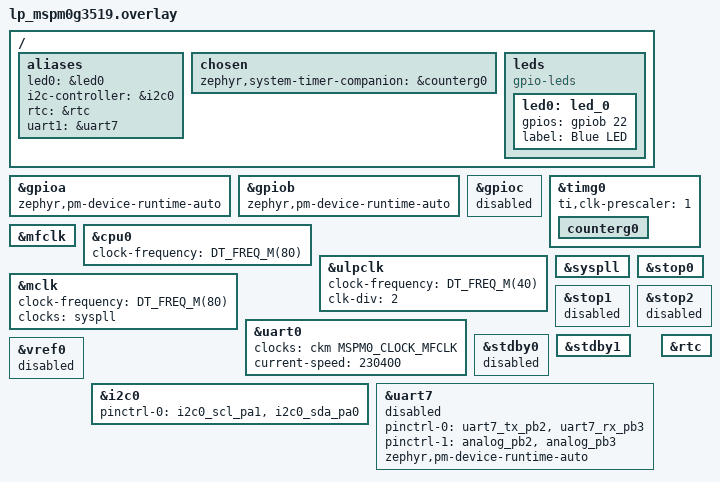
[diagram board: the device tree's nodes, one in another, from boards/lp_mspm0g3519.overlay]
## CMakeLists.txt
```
# SPDX-License-Identifier: Apache-2.0

cmake_minimum_required(VERSION 3.20.0)
find_package(Zephyr REQUIRED HINTS $ENV{ZEPHYR_BASE})
project(full_pm)

target_sources(app PRIVATE src/main.c)
```

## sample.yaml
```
sample:
  name: Complex Power Management Sample
tests:
  ti_samples.full_pm:
    tags:
      - LED
      - uart
      - i2c
      - rtc
      - gpio
      - pm
    depends_on: gpio
    harness: led
    integration_platforms:
      - lp_mspm0g3519
```

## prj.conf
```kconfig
CONFIG_GPIO=y

# Low power
CONFIG_PM=y
CONFIG_PM_DEVICE=y
# CONFIG_PM_DEVICE_RUNTIME=y
# CONFIG_PM_DEVICE_RUNTIME_DEFAULT_ENABLE=y
CONFIG_PM_POLICY_DEFAULT=y
CONFIG_IDLE_STACK_SIZE=2048
CONFIG_SYSTEM_TIMER_LPM_COMPANION_COUNTER=y
CONFIG_COUNTER=y
CONFIG_PM_PREWAKEUP_CONV_MODE_CEIL=y
CONFIG_SYS_CLOCK_EXISTS=y
CONFIG_SYSTEM_CLOCK_HW_CYCLES_PER_SEC_RUNTIME_UPDATE=y

CONFIG_SYSTEM_TIMER_RESET_BY_LPM=y #does this create a hard fault?

CONFIG_SERIAL=y
CONFIG_CONSOLE=y
CONFIG_UART_CONSOLE=y

# CONFIG_UART_INTERRUPT_DRIVEN=y

CONFIG_I2C=y
CONFIG_I2C_SCL_LOW_TIMEOUT_MS=0

CONFIG_RTC=y

# CONFIG_SHELL=y
```

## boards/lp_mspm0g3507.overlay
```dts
/*
 * Copyright (c) 2026 Texas Instruments
 *
 * SPDX-License-Identifier: Apache-2.0
 */

/ {
	aliases {
		led0 = &led0;
	};

	chosen {
		zephyr,system-timer-companion = &counterg0;
	};

	leds {
		compatible = "gpio-leds";

		led0: led_0 {
			gpios = <&gpiob 22 GPIO_ACTIVE_LOW>;
			label = "Blue LED";
		};
	};
};

&gpiob {
	status = "okay";
	zephyr,pm-device-runtime-auto;
};

&timg0 {
	status = "okay";
	ti,clk-prescaler = <1>;

	counterg0 {
		status = "okay";
	};
};

&mfclk {
	status = "okay";
};

&uart0 {
	clocks = <&ckm MSPM0_CLOCK_MFCLK>;
	current-speed = <460800>;
};

&lfclk {
	clocks = <&lfxt>;
};

&lfxt {
	status = "okay";
	clock-frequency = <32768>;
};

&stop1 {
	status = "disabled";
};

&stop2 {
	status = "disabled";
};

&stdby0 {
	status = "disabled";
};

&stdby1 {
	status = "okay";
};

&vref0 {
	status = "disabled";
};
```

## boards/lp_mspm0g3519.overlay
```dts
/*
 * Copyright (c) 2026 Texas Instruments
 *
 * SPDX-License-Identifier: Apache-2.0
 */

/ {
	aliases {
		led0 = &led0;
		i2c-controller = &i2c0;
		rtc = &rtc;
		uart1 = &uart7;
	};

	chosen {
		zephyr,system-timer-companion = &counterg0;
	};

	leds {
		compatible = "gpio-leds";

		led0: led_0 {
			gpios = <&gpiob 22 GPIO_ACTIVE_HIGH>;
			label = "Blue LED";
		};
	};
};

&gpioa {
	status = "okay";
	zephyr,pm-device-runtime-auto;
};

&gpiob {
	status = "okay";
	zephyr,pm-device-runtime-auto;
};

&gpioc {
	status = "disabled";
};

&timg0 {
	status = "okay";
	ti,clk-prescaler = <1>;

	counterg0 {
		status = "okay";
	};
};

&mfclk {
	status = "okay";
};

&cpu0 {
	clock-frequency = <DT_FREQ_M(80)>;
};

&ulpclk {
	clock-frequency = <DT_FREQ_M(40)>;
	clk-div = <2>;
};

&mclk {
	clock-frequency = <DT_FREQ_M(80)>;
	clocks = <&syspll>;
};

&syspll {
	status = "okay";
};

&uart0 {
	clocks = <&ckm MSPM0_CLOCK_MFCLK>;
	current-speed = <230400>;
	/delete-property/ zephyr,pm-device-runtime-auto;
};

&stop0 {
	status = "okay";
};

&stop1 {
	status = "disabled";
};

&stop2 {
	status = "disabled";
};

&stdby0 {
	status = "disabled";
};

&stdby1 {
	status = "okay";
};

&vref0 {
	status = "disabled";
};

&i2c0 {
	pinctrl-0 = <&i2c0_scl_pa1 &i2c0_sda_pa0>;
	pinctrl-names = "default";
	status = "okay";
};

&uart7 {
	pinctrl-0 = <&uart7_tx_pb2 &uart7_rx_pb3>;
	pinctrl-1 = <&analog_pb2 &analog_pb3>;
	pinctrl-names = "default", "sleep";
	status = "disabled";
	zephyr,pm-device-runtime-auto;
};

&rtc {
	status = "okay";
};
```

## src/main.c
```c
/*
 * Copyright (c) 2016 Intel Corporation
 * Copyright (c) 2026 Texas Instruments
 *
 * SPDX-License-Identifier: Apache-2.0
 */

#include <stdio.h>
#include <zephyr/kernel.h>
#include <zephyr/drivers/gpio.h>
#include <zephyr/drivers/i2c.h>
#include <zephyr/drivers/rtc.h>
#include <zephyr/drivers/clock_control/mspm0_clock_control.h>
#include <ti/driverlib/driverlib.h>
#include <zephyr/pm/policy.h>

/* 1000 msec = 1 sec */
#define SLEEP_TIME_MS   2000

/* PA22 for CLK_OUT */
#define GPIO_CLKOUT_PIN                                           DL_GPIO_PIN_22
#define GPIO_CLKOUT_PORT                                                   GPIOA
#define GPIO_CLKOUT_IOMUX                                        (IOMUX_PINCM47)
#define GPIO_CLKOUT_IOMUX_FUNC                   IOMUX_PINCM47_PF_SYSCTL_CLK_OUT

/* TODO: remove */
#define DEBUG_POWER_GPIO_PIN (DL_GPIO_PIN_20)
#define DEBUG_POWER_GPIO_PORT (GPIOB)
#define DEBUG_POWER_GPIO_IOMUX (IOMUX_PINCM48)

#define DEBUG_IDLE_GPIO_PIN (DL_GPIO_PIN_21)
#define DEBUG_IDLE_GPIO_PORT (GPIOB)
#define DEBUG_IDLE_GPIO_IOMUX (IOMUX_PINCM49)

#define DEBUG_ASYNC_GPIO_PIN (DL_GPIO_PIN_30)
#define DEBUG_ASYNC_GPIO_PORT (GPIOB)
#define DEBUG_ASYNC_GPIO_IOMUX (IOMUX_PINCM67)

#define DEBUG_CLOCK_GPIO_PIN (DL_GPIO_PIN_31)
#define DEBUG_CLOCK_GPIO_PORT (GPIOB)
#define DEBUG_CLOCK_GPIO_IOMUX (IOMUX_PINCM68)

#define DEBUG_FCC_GPIO_PIN (DL_GPIO_PIN_25)
#define DEBUG_FCC_GPIO_PORT (GPIOB)
#define DEBUG_FCC_GPIO_IOMUX (IOMUX_PINCM56)

#define DEBUG_FAIL_GPIO_PORT (GPIOB)
#define DEBUG_FAIL_GPIO_PIN (DL_GPIO_PIN_26)
#define DEBUG_FAIL_GPIO_IOMUX (IOMUX_PINCM57)

/*
 * A build error on this line means your board is unsupported.
 * See the sample documentation for information on how to fix this.
 */
#define LED0_NODE DT_ALIAS(led0)
static const struct gpio_dt_spec led = GPIO_DT_SPEC_GET(LED0_NODE, gpios);

#define TARGET_ADDR 0x32

uint8_t i2c_data[] = {0xA0, 0xA1, 0xA2, 0xA3, 0xA4, 0xA5, 0xA6, 0xA7, 0xA8, 0xA9, 0xAA, 0xAB, 0xAC, 0xAD, 0xAE, 0x00};

#define I2C_CONTROLLER_NODE DT_ALIAS(i2c_controller)

static const struct device *i2c_dev = DEVICE_DT_GET(I2C_CONTROLLER_NODE);

static const struct device *const rtc = DEVICE_DT_GET(DT_ALIAS(rtc));

static int set_date_time(const struct device *rtc)
{
	int ret = 0;
	struct rtc_time tm = {
		.tm_year = 2026 - 1900,
		.tm_mon = 6 - 1,
		.tm_mday = 4,
		.tm_hour = 0,
		.tm_min = 0,
		.tm_sec = 0,
	};

	ret = rtc_set_time(rtc, &tm);

	return ret;
}

static int get_date_time(const struct device *rtc)
{
	int ret = 0;
	struct rtc_time tm;

	ret = rtc_get_time(rtc, &tm);
	if (ret < 0) {
		return ret;
	}

	printk("RTC date and time: %04d-%02d-%02d %02d:%02d:%02d\n", tm.tm_year + 1900,
	       tm.tm_mon + 1, tm.tm_mday, tm.tm_hour, tm.tm_min, tm.tm_sec);

	return ret;
}

int main(void)
{
	int ret;
	int64_t uptime_ms;

	DL_GPIO_enablePower(GPIOA);
	delay_cycles(16);
	DL_GPIO_initPeripheralOutputFunction(GPIO_CLKOUT_IOMUX, GPIO_CLKOUT_IOMUX_FUNC);
	DL_GPIO_enableOutput(GPIO_CLKOUT_PORT, GPIO_CLKOUT_PIN);
	DL_SYSCTL_enableExternalClock(DL_SYSCTL_CLK_OUT_SOURCE_ULPCLK, DL_SYSCTL_CLK_OUT_DIVIDE_16);

	/* Begin DEBUG ONLY */
	DL_GPIO_initDigitalOutput(DEBUG_POWER_GPIO_IOMUX);
	DL_GPIO_enableOutput(DEBUG_POWER_GPIO_PORT, DEBUG_POWER_GPIO_PIN);
	DL_GPIO_setPins(DEBUG_POWER_GPIO_PORT, DEBUG_POWER_GPIO_PIN);

	DL_GPIO_initDigitalOutput(DEBUG_IDLE_GPIO_IOMUX);
	DL_GPIO_enableOutput(DEBUG_IDLE_GPIO_PORT, DEBUG_IDLE_GPIO_PIN);
	DL_GPIO_setPins(DEBUG_IDLE_GPIO_PORT, DEBUG_IDLE_GPIO_PIN);

	DL_GPIO_initDigitalOutput(DEBUG_ASYNC_GPIO_IOMUX);
	DL_GPIO_enableOutput(DEBUG_ASYNC_GPIO_PORT, DEBUG_ASYNC_GPIO_PIN);
	DL_GPIO_clearPins(DEBUG_ASYNC_GPIO_PORT, DEBUG_ASYNC_GPIO_PIN);

	DL_GPIO_initDigitalOutput(DEBUG_CLOCK_GPIO_IOMUX);
	DL_GPIO_initDigitalOutput(DEBUG_FCC_GPIO_IOMUX);
	DL_GPIO_initDigitalOutput(DEBUG_FAIL_GPIO_IOMUX);
	DL_GPIO_enableOutput(DEBUG_CLOCK_GPIO_PORT, DEBUG_CLOCK_GPIO_PIN | DEBUG_FCC_GPIO_PIN | DEBUG_FAIL_GPIO_PIN);
	DL_GPIO_clearPins(DEBUG_CLOCK_GPIO_PORT, DEBUG_CLOCK_GPIO_PIN | DEBUG_FCC_GPIO_PIN | DEBUG_FAIL_GPIO_PIN);

	/* END DEBUG ONLY */

	if (!gpio_is_ready_dt(&led)) {
		return 0;
	}

	if (!device_is_ready(i2c_dev)){
		return 0;
	}

	if (!device_is_ready(rtc)) {
		return 0;
	}

	set_date_time(rtc);


	ret = gpio_pin_configure_dt(&led, GPIO_OUTPUT_INACTIVE);
	if (ret < 0) {
		return 0;
	}

	printf("Hello from TI\n");

	while (1) {
		ret = gpio_pin_set_dt(&led, 1);
		if (ret < 0) {
			return 0;
		}

		uptime_ms = k_uptime_get();
		printk("System uptime: %lld ms\n", uptime_ms);

		/* send an i2c transaction */
		i2c_write(i2c_dev, i2c_data, 10, TARGET_ADDR);

		i2c_data[15]++;

		ret = get_date_time(rtc);

		ret = gpio_pin_set_dt(&led, 0);

		/* During this k_msleep(), the PM policy manager automatically
		 * selects an appropriate SoC sleep state and the system enters
		 * low-power mode. Timer interrupt wakes the system after 1000ms.
		 */

		k_msleep(SLEEP_TIME_MS);
	}
	return 0;
}
```
